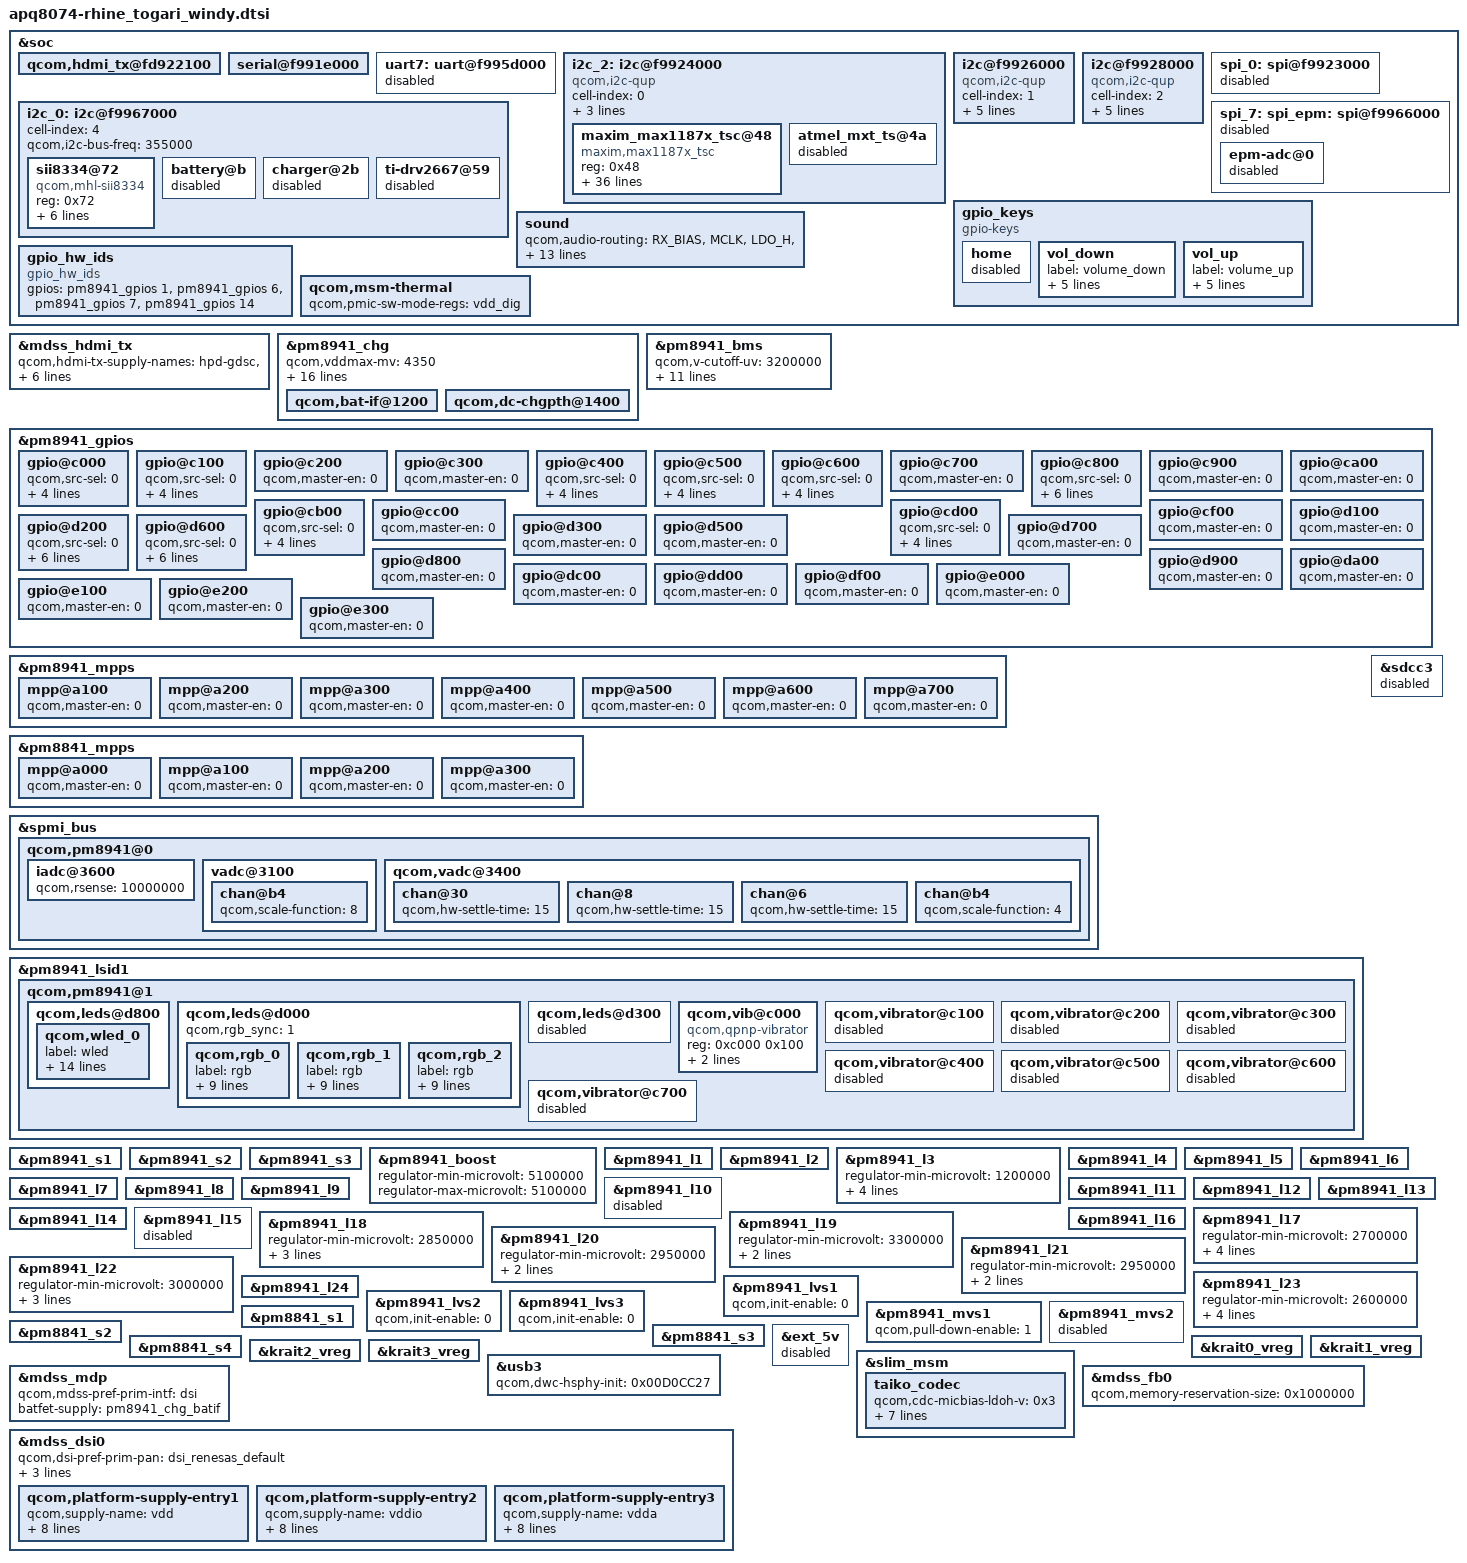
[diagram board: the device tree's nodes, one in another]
/* arch/arm/boot/dts/apq8074-rhine_togari_windy.dtsi
 *
 * Copyright (C) 2013 Sony Mobile Communications AB.
 *
 * Author: Shougo Watanabe <Shougo.X.Watanabe@sonymobile.com>
 *
 * This program is free software; you can redistribute it and/or modify
 * it under the terms of the GNU General Public License version 2 and
 * only version 2 as published by the Free Software Foundation.
 *
 * This program is distributed in the hope that it will be useful,
 * but WITHOUT ANY WARRANTY; without even the implied warranty of
 * MERCHANTABILITY or FITNESS FOR A PARTICULAR PURPOSE.  See the
 * GNU General Public License for more details.
 */

/include/ "dsi-panel-togari.dtsi"

&soc {
	qcom,hdmi_tx@fd922100 {
		status = "ok";
	};

	/* BLSP2 */
	serial@f991e000 {
		status = "ok";
	};

	/* BLSP7 */
	uart7: uart@f995d000 {
		status = "disabled";
	};

	/* BLSP2 */
	i2c_2: i2c@f9924000 {
		cell-index = <0>;
		compatible = "qcom,i2c-qup";
		qcom,i2c-bus-freq = <355000>;
		qcom,scl-gpio = <&msmgpio 7 0x00>;
		qcom,sda-gpio = <&msmgpio 6 0x00>;
		status = "ok";
		maxim_max1187x_tsc@48 {
			compatible = "maxim,max1187x_tsc";
			reg = <0x48>;
			interrupt-parent = <&msmgpio>;
			interrupts = <61 0x2>;
			touch_vdd-supply = <&pm8941_l22>;
			touch_vdd-supply_name = "touch_vdd";
			gpio_tirq = <61>;
			gpio_pwr_en = <85>;
			num_fw_mappings = <5>;
			config_id = <0x0460 0x0010 0x0011 0x0012 0x0013>;
			chip_id = <0x74 0x75 0x74 0x75 0x75>;
			filename = "touch_chip_id_0x74_config_id_0x0460.bin",
				   "touch_chip_id_0x75_config_id_0x0010.bin",
				   "touch_chip_id_0x74_config_id_0x0011.bin",
				   "touch_chip_id_0x75_config_id_0x0012.bin",
				   "touch_chip_id_0x75_config_id_0x0013.bin";
			filesize = <0xC000 0xC000 0xC000 0xC000 0xC000>;
			file_codesize = <0xC000 0xC000 0xC000 0xC000 0xC000>;
			defaults_allow = <0>;
			default_config_id = <0>;
			default_chip_id = <0>;
			i2c_words = <128>;
			coordinate_settings = <0x4>;
			panel_margin_xl = <0>;
			lcd_x = <1080>;
			panel_margin_xh = <0>;
			panel_margin_yl = <0>;
			lcd_y = <1920>;
			panel_margin_yh = <0>;
			num_sensor_x = <24>;
			num_sensor_y = <40>;
			button_code0 = <0>;
			button_code1 = <0>;
			button_code2 = <0>;
			button_code3 = <0>;
			enable_resume_por = <1>;
		};

		atmel_mxt_ts@4a {
			status = "disabled";
		};
	};

	/* BLSP4 */
	i2c@f9926000 {
		cell-index = <1>;
		compatible = "qcom,i2c-qup";
		reg = <0xf9926000 0x1000>;
		#address-cells = <1>;
		#size-cells = <0>;
		reg-names = "qup_phys_addr";
		interrupts = <0 98 0>;
		interrupt-names = "qup_err_intr";
		qcom,i2c-bus-freq = <355000>;
		qcom,i2c-src-freq = <50000000>;
		qcom,master-id = <86>;
		status = "ok";
	};

	/* BLSP6 */
	i2c@f9928000 {
		cell-index = <2>;
		compatible = "qcom,i2c-qup";
		reg = <0xf9928000 0x1000>;
		#address-cells = <1>;
		#size-cells = <0>;
		reg-names = "qup_phys_addr";
		interrupts = <0 100 0>;
		interrupt-names = "qup_err_intr";
		qcom,i2c-bus-freq = <355000>;
		qcom,i2c-src-freq = <50000000>;
		qcom,master-id = <86>;
		status = "ok";
	};

	/* BLSP11 */
	i2c_0: i2c@f9967000 {
		cell-index = <4>;
		qcom,i2c-bus-freq = <355000>;
		status = "ok";
		sii8334@72 {
			compatible = "qcom,mhl-sii8334";
			reg = <0x72>;
			interrupt-parent = <&msmgpio>;
			interrupts = <64 0x2008>;
			mhl-intr-gpio = <&msmgpio 64 0>;
			mhl-pwr-gpio = <&msmgpio 60 0>;
			mhl-rst-gpio = <&msmgpio 16 0>;
			qcom,hdmi-tx-map = <&mdss_hdmi_tx>;
		};

		battery@b {
			status = "disabled";
		};

		charger@2b {
			status = "disabled";
		};

		ti-drv2667@59 {
			status = "disabled";
		};
	};

	/* BLSP1 */
	spi_0: spi@f9923000 {
		status = "disabled";
	};

	/* BLSP10 */
	spi_7: spi_epm: spi@f9966000 {
		status = "disabled";

		epm-adc@0 {
			status = "disabled";
		};
	};

	gpio_keys {
		compatible = "gpio-keys";

		home {
			status = "disabled";
		};

		vol_down {
			label = "volume_down";
			gpios = <&pm8941_gpios 2 0x1>;
			linux,input-type = <1>;
			linux,code = <114>;
			gpio-key,wakeup;
			debounce-interval = <15>;
		};

		vol_up {
			label = "volume_up";
			gpios = <&pm8941_gpios 5 0x1>;
			linux,input-type = <1>;
			linux,code = <115>;
			gpio-key,wakeup;
			debounce-interval = <15>;
		};
	};

	sound {
		qcom,audio-routing =
			"RX_BIAS", "MCLK",
			"LDO_H", "MCLK",
			"Ext Spk Bottom Pos", "LINEOUT1",
			"Ext Spk Bottom Neg", "LINEOUT3",
			"Ext Spk Top Pos", "LINEOUT2",
			"Ext Spk Top Neg", "LINEOUT4",
			"AMIC1", "MIC BIAS1 External",
			"MIC BIAS1 External", "Handset Mic",
			"AMIC2", "MIC BIAS2 External",
			"MIC BIAS2 External", "Headset Mic",
			"AMIC3", "MIC BIAS3 External",
			"MIC BIAS3 External", "ANCLeft Headset Mic",
			"AMIC4", "MIC BIAS1 External",
			"MIC BIAS1 External", "Handset Mic",
			"AMIC5", "MIC BIAS1 External",
			"MIC BIAS1 External", "Secondary Mic",
			"AMIC6", "MIC BIAS4 External",
			"MIC BIAS4 External", "Handset FB ANC Mic";

		/delete-property/ qcom,ext-spk-amp-supply;
		/delete-property/ qcom,ext-spk-amp-gpio;
		/delete-property/ qcom,dock-plug-det-irq;
		/delete-property/ qcom,ext-ult-spk-amp-gpio;
	};

	gpio_hw_ids {
		compatible = "gpio_hw_ids";

		gpios = <&pm8941_gpios 1 0>,
			<&pm8941_gpios 6 0>,
			<&pm8941_gpios 7 0>,
			<&pm8941_gpios 14 0>;
	};

	qcom,msm-thermal {
		qcom,pmic-sw-mode-regs = "vdd_dig";
	};

	/delete-node/ ath_chip_reset;
	/delete-node/ bt_ar3002;
	/delete-node/ bt_ar3002_sleep;
	/delete-node/ qca,wlan;
	/delete-node/ qca,wlan_sdio;
};

&mdss_hdmi_tx {
	/* rhine doesn't use hpd-5v */
	qcom,hdmi-tx-supply-names = "hpd-gdsc", "core-vdda", "core-vcc";
	qcom,hdmi-tx-min-voltage-level = <0 1800000 1800000>;
	qcom,hdmi-tx-max-voltage-level = <0 1800000 1800000>;
	qcom,hdmi-tx-peak-current = <0 300000 0>;
};

&pm8941_chg {
	qcom,vddmax-mv = <4350>;
	qcom,vddsafe-mv = <4400>;
	qcom,ibatmax-ma = <2000>;
	qcom,ibatterm-ma = <150>;
	qcom,ibatsafe-ma = <2000>;
	qcom,maxinput-dc-ma = <1800>;
	qcom,maxinput-usb-ma = <1500>;
	qcom,cool-bat-mv = <4350>;
	qcom,ibatmax-warm-ma = <900>;
	qcom,warm-bat-mv = <4200>;
	qcom,ibatmax-cool-ma = <900>;
	qcom,vbatdet-delta-mv = <20>;
	qcom,vbatdet-delta-soc = <1>;
	qcom,thermal-mitigation = <2000 1500 1100 900 700 500 300 200 100 0>;
	qcom,tchg-mins = <512>;
	otg-parent-supply = <&pm8941_boost>;

	qcom,bat-if@1200 {
		status = "ok";
	};

	qcom,dc-chgpth@1400 {
		status = "ok";
	};
};

&pm8941_bms {
	status = "ok";
	qcom,v-cutoff-uv = <3200000>;
	qcom,max-voltage-uv = <4350000>;
	qcom,r-conn-mohm = <0>;
	qcom,low-soc-calculate-soc-threshold = <5>;
	qcom,low-soc-calculate-soc-ms = <1000>;
	qcom,calculate-soc-ms = <30000>;
	qcom,chg-term-ua = <150000>;
	qcom,use-external-rsense = <1>;
	qcom,batt-type = <3>;
	qcom,shutdown-soc-valid-limit = <40>;
	qcom,clamp-soc-max-count = <2>;
	qcom,fcc-resolution = <13>;
};

&pm8941_gpios {
	/* GPIO_1: HW_ID_0 */
	gpio@c000 {
		qcom,src-sel = <0>;		/* GPIO */
		qcom,mode = <0>;		/* In */
		qcom,vin-sel = <2>;		/* S3 */
		qcom,pull = <5>;		/* NP */
		qcom,master-en = <1>;		/* Enable */
		status = "ok";
	};

	/* GPIO_2: VOL_DN */
	gpio@c100 {
		qcom,src-sel = <0>;		/* GPIO */
		qcom,mode = <0>;		/* In */
		qcom,vin-sel = <2>;		/* S3 */
		qcom,pull = <0>;		/* PU */
		qcom,master-en = <1>;		/* Enable */
		status = "ok";
	};

	/* GPIO_3: NC (SNAPSHOT) */
	gpio@c200 {
		qcom,master-en = <0>;		/* Disable */
		status = "ok";
	};

	/* GPIO_4: NC (FOCUS) */
	gpio@c300 {
		qcom,master-en = <0>;		/* Disable */
		status = "ok";
	};

	/* GPIO_5: VOL_UP */
	gpio@c400 {
		qcom,src-sel = <0>;		/* GPIO */
		qcom,mode = <0>;		/* In */
		qcom,vin-sel = <2>;		/* S3 */
		qcom,pull = <0>;		/* PU */
		qcom,master-en = <1>;		/* Enable */
		status = "ok";
	};

	/* GPIO_6: HW_ID_1 */
	gpio@c500 {
		qcom,src-sel = <0>;		/* GPIO */
		qcom,mode = <0>;		/* In */
		qcom,vin-sel = <2>;		/* S3 */
		qcom,pull = <5>;		/* NP */
		qcom,master-en = <1>;		/* Enable */
		status = "ok";
	};

	/* GPIO_7: HW_ID_2 */
	gpio@c600 {
		qcom,src-sel = <0>;		/* GPIO */
		qcom,mode = <0>;		/* In */
		qcom,vin-sel = <2>;		/* S3 */
		qcom,pull = <5>;		/* NP */
		qcom,master-en = <1>;		/* Enable */
		status = "ok";
	};

	/* GPIO_8: NC */
	gpio@c700 {
		qcom,master-en = <0>;		/* Disable */
		status = "ok";
	};

	/* GPIO_9: RF_ID_EN */
	gpio@c800 {
		qcom,src-sel = <0>;		/* GPIO */
		qcom,mode = <1>;		/* Out */
		qcom,output-type = <0>;		/* CMOS */
		qcom,vin-sel = <2>;		/* S3 */
		qcom,out-strength = <3>;	/* High */
		qcom,invert = <0>;		/* Low */
		qcom,master-en = <1>;		/* Enable */
		status = "ok";
	};

	/* GPIO_10: NC (FCHG_CNT) */
	gpio@c900 {
		qcom,master-en = <0>;		/* Disable */
		status = "ok";
	};

	/* GPIO_11: NC (AUD_DSP_PWR_EN) */
	gpio@ca00 {
		qcom,master-en = <0>;		/* Disable */
		status = "ok";
	};

	/* GPIO_12: RF_ID_EXTENTION */
	gpio@cb00 {
		qcom,src-sel = <0>;		/* GPIO */
		qcom,mode = <0>;		/* In */
		qcom,vin-sel = <2>;		/* S3 */
		qcom,pull = <4>;		/* PD */
		qcom,master-en = <1>;		/* Enable */
		status = "ok";
	};

	/* GPIO_13: NC (TUNER_STATUS0) */
	gpio@cc00 {
		qcom,master-en = <0>;		/* Disable */
		status = "ok";
	};

	/* GPIO_14: HW_ID_3 */
	gpio@cd00 {
		qcom,src-sel = <0>;		/* GPIO */
		qcom,mode = <0>;		/* In */
		qcom,vin-sel = <2>;		/* S3 */
		qcom,pull = <4>;		/* PD */
		qcom,master-en = <1>;		/* Enable */
		status = "ok";
	};

	/* GPIO_15: DIVCLK1_CODEC */
	/* Follow QCT */

	/* GPIO_16: NC */
	gpio@cf00 {
		qcom,master-en = <0>;		/* Disable */
		status = "ok";
	};

	/* GPIO_17: (DIVCLK3) QPA_XO */
	/* Follow QCT */

	/* GPIO_18: NC (TUNER_STATUS1) */
	gpio@d100 {
		qcom,master-en = <0>;		/* Disable */
		status = "ok";
	};

	/* GPIO_19: DISP_RESET_N */
	gpio@d200 {
		qcom,src-sel = <0>;		/* GPIO */
		qcom,mode = <1>;		/* Out */
		qcom,output-type = <0>;		/* CMOS */
		qcom,vin-sel = <2>;		/* S3 */
		qcom,out-strength = <1>;	/* Low */
		qcom,invert = <0>;		/* Low */
		qcom,master-en = <1>;		/* Enable */
		status = "ok";
	};

	/* GPIO_20: NC (IR_LEVEL_EN) */
	gpio@d300 {
		qcom,master-en = <0>;		/* Disable */
		status = "ok";
	};

	/* GPIO_21: BOOST_BYP_EN */
	/* Follow QCT */

	/* GPIO_22: NC (HS_DET) */
	gpio@d500 {
		qcom,master-en = <0>;		/* Disable */
		status = "ok";
	};

	/* GPIO_23: NFC_VEN */
	gpio@d600 {
		qcom,src-sel = <0>;		/* GPIO */
		qcom,mode = <1>;		/* Out */
		qcom,output-type = <0>;		/* CMOS */
		qcom,vin-sel = <2>;		/* S3 */
		qcom,out-strength = <1>;	/* Low */
		qcom,invert = <1>;		/* High */
		qcom,master-en = <1>;		/* Enable */
		status = "ok";
	};

	/* GPIO_24: NC (NFC_EXT_LDO_EN) */
	gpio@d700 {
		qcom,master-en = <0>;		/* Disable */
		status = "ok";
	};

	/* GPIO_25: NC (IR_RESET) */
	gpio@d800 {
		qcom,master-en = <0>;		/* Disable */
		status = "ok";
	};

	/* GPIO_26: NC (TUNER_ANT_SW_EN) */
	gpio@d900 {
		qcom,master-en = <0>;		/* Disable */
		status = "ok";
	};

	/* GPIO_27: NC (FLASH_LED_NOW) */
	gpio@da00 {
		qcom,master-en = <0>;		/* Disable */
		status = "ok";
	};

	/* GPIO_28: TX_GTR_THRES */
	/* Follow QCT */

	/* GPIO_29: NC */
	gpio@dc00 {
		qcom,master-en = <0>;		/* Disable */
		status = "ok";
	};

	/* GPIO_30: NC */
	gpio@dd00 {
		qcom,master-en = <0>;		/* Disable */
		status = "ok";
	};

	/* GPIO_31: BATT_REM_ALERM */
	/* Follow QCT */

	/* GPIO_32: NC (TUNER_ANT_SW1) */
	gpio@df00 {
		qcom,master-en = <0>;		/* Disable */
		status = "ok";
	};

	/* GPIO_33: NC (FELICA_FF) */
	gpio@e000 {
		qcom,master-en = <0>;		/* Disable */
		status = "ok";
	};

	/* GPIO_34: NC (FELICA_LOCK) */
	gpio@e100 {
		qcom,master-en = <0>;		/* Disable */
		status = "ok";
	};

	/* GPIO_35: NC (Reserved for ANC_HS_DET) */
	gpio@e200 {
		qcom,master-en = <0>;		/* Disable */
		status = "ok";
	};

	/* GPIO_36: NC */
	gpio@e300 {
		qcom,master-en = <0>;		/* Disable */
		status = "ok";
	};
};

&pm8941_mpps {
	/* MPP_1: SDC_UIM_VBIAS */
	/* Follow QCT */

	/* MPP_2: NC */
	mpp@a100 {
		qcom,master-en = <0>;		/* Disable */
		status = "ok";
	};

	/* MPP_3: NC */
	mpp@a200 {
		qcom,master-en = <0>;		/* Disable */
		status = "ok";
	};

	/* MPP_4: NC */
	mpp@a300 {
		qcom,master-en = <0>;		/* Disable */
		status = "ok";
	};

	/* MPP_5: NC */
	mpp@a400 {
		qcom,master-en = <0>;		/* Disable */
		status = "ok";
	};

	/* MPP_6: NC (ACC_ADC) */
	mpp@a500 {
		qcom,master-en = <0>;		/* Disable */
		status = "ok";
	};

	/* MPP_7: RF_ID */
	mpp@a600 {
		qcom,master-en = <0>;		/* Disable */
		status = "ok";
	};

	/* MPP_8: NC */
	mpp@a700 {
		qcom,master-en = <0>;		/* Disable */
		status = "ok";
	};
};

&pm8841_mpps {
	/* MPP_1: NC (LMU_EN) */
	mpp@a000 {
		qcom,master-en = <0>;		/* Disable */
		status = "ok";
	};

	/* MPP_2: NC (FLASH_DR_RST_N) */
	mpp@a100 {
		qcom,master-en = <0>;		/* Disable */
		status = "ok";
	};

	/* MPP_3: NC */
	mpp@a200 {
		qcom,master-en = <0>;		/* Disable */
		status = "ok";
	};

	/* MPP_4: NC */
	mpp@a300 {
		qcom,master-en = <0>;		/* Disable */
		status = "ok";
	};
};

&spmi_bus {
	qcom,pm8941@0 {
		iadc@3600 {
			qcom,rsense = <10000000>;
		};
	};
};

&pm8941_lsid1 {
	qcom,pm8941@1 {
		qcom,leds@d800 {
			status = "okay";
			qcom,wled_0 {
				label = "wled";
				linux,name = "wled:backlight";
				linux,default-trigger = "bkl-trigger";
				qcom,cs-out-en = <1>;
				qcom,cabc-en = <1>;
				qcom,op-fdbck = <0>;
				qcom,default-state = "on";
				qcom,max-current = <20>;
				qcom,ctrl-delay-us = <0>;
				qcom,boost-curr-lim = <3>;
				qcom,cp-sel = <0>;
				qcom,switch-freq = <2>;
				qcom,ovp-val = <2>;
				qcom,num-strings = <2>;
				qcom,id = <0>;
			};
		};

		qcom,leds@d000 {
			status = "okay";
			qcom,rgb_sync = <1>;

			qcom,rgb_0 {
				label = "rgb";
				linux,name = "led:rgb_red";
				qcom,mode = "pwm";
				qcom,pwm-channel = <6>;
				qcom,pwm-us = <1000>;
				qcom,pwm-max-value = <31>;
				qcom,max-current = <12>;
				qcom,default-state = "off";
				qcom,id = <3>;
				linux,default-trigger = "none";
			};

			qcom,rgb_1 {
				label = "rgb";
				linux,name = "led:rgb_green";
				qcom,mode = "pwm";
				qcom,pwm-channel = <5>;
				qcom,pwm-us = <1000>;
				qcom,pwm-max-value = <32>;
				qcom,max-current = <12>;
				qcom,default-state = "off";
				qcom,id = <4>;
				linux,default-trigger = "none";
			};

			qcom,rgb_2 {
				label = "rgb";
				linux,name = "led:rgb_blue";
				qcom,mode = "pwm";
				qcom,pwm-channel = <4>;
				qcom,pwm-us = <1000>;
				qcom,pwm-max-value = <24>;
				qcom,max-current = <12>;
				qcom,default-state = "off";
				qcom,id = <5>;
				linux,default-trigger = "none";
			};
		};

		qcom,leds@d300 {
			status = "disabled";
		};

		qcom,vib@c000 {
			status = "okay";
			compatible = "qcom,qpnp-vibrator";
			reg = <0xc000 0x100>;
			label = "vibrator";
			qcom,qpnp-vib-vtg-level-mV = <3100>;
		};

		qcom,vibrator@c100 {
			status = "disabled";
		};

		qcom,vibrator@c200 {
			status = "disabled";
		};

		qcom,vibrator@c300 {
			status = "disabled";
		};

		qcom,vibrator@c400 {
			status = "disabled";
		};

		qcom,vibrator@c500 {
			status = "disabled";
		};

		qcom,vibrator@c600 {
			status = "disabled";
		};

		qcom,vibrator@c700 {
			status = "disabled";
		};
	};
};

&sdcc3 {
	status = "disable";
};

/* Regulator config */
&pm8941_s1 {
	status = "ok";
};

&pm8941_s2 {
	status = "ok";
};

&pm8941_s3 {
	status = "ok";
};

&pm8941_boost { /* VREG_5V */
	regulator-min-microvolt = <5100000>;
	regulator-max-microvolt = <5100000>;
	status = "ok";
};

&pm8941_l1 {
	status = "ok";
};

&pm8941_l2 {
	status = "ok";
};

&pm8941_l3 {
	regulator-min-microvolt = <1200000>;
	regulator-max-microvolt = <1200000>;
	qcom,init-enable = <0>;
	qcom,init-voltage = <1200000>;
	qcom,init-ldo-mode = <1>;
	status = "ok";
};

&pm8941_l4 {
	status = "ok";
};

&pm8941_l5 {
	status = "ok";
};

&pm8941_l6 {
	status = "ok";
};

&pm8941_l7 {
	status = "ok";
};

&pm8941_l8 {
	status = "ok";
};

&pm8941_l9 {
	status = "ok";
};

&pm8941_l10 {
	status = "disabled";
};

&pm8941_l11 {
	status = "ok";
};

&pm8941_l12 {
	status = "ok";
};

&pm8941_l13 {
	status = "ok";
};

&pm8941_l14 {
	status = "ok";
};

&pm8941_l15 {
	status = "disabled";
};

&pm8941_l16 {
	status = "ok";
};

&pm8941_l17 {
	regulator-min-microvolt = <2700000>;
	regulator-max-microvolt = <2700000>;
	qcom,init-enable = <0>;
	qcom,init-voltage = <2700000>;
	qcom,init-ldo-mode = <1>;
	status = "ok";
};

&pm8941_l18 {
	regulator-min-microvolt = <2850000>;
	regulator-max-microvolt = <2850000>;
	qcom,init-enable = <0>;
	qcom,init-voltage = <2850000>;
	status = "ok";
};

&pm8941_l19 {
	regulator-min-microvolt = <3300000>;
	regulator-max-microvolt = <3300000>;
	qcom,init-voltage = <3300000>;
	status = "ok";
};

&pm8941_l20 {
	regulator-min-microvolt = <2950000>;
	regulator-max-microvolt = <2950000>;
	qcom,init-voltage = <2950000>;
	status = "ok";
};

&pm8941_l21 {
	regulator-min-microvolt = <2950000>;
	regulator-max-microvolt = <2950000>;
	qcom,init-voltage = <2950000>;
	status = "ok";
};

&pm8941_l22 {
	regulator-min-microvolt = <3000000>;
	regulator-max-microvolt = <3000000>;
	qcom,init-enable = <0>;
	qcom,init-voltage = <3000000>;
	status = "ok";
};

&pm8941_l23 {
	regulator-min-microvolt = <2600000>;
	regulator-max-microvolt = <2600000>;
	qcom,init-enable = <0>;
	qcom,init-voltage = <2600000>;
	qcom,init-ldo-mode = <1>;
	status = "ok";
};

&pm8941_l24 {
	status = "ok";
};

&pm8941_lvs1 {
	qcom,init-enable = <0>;
	status = "ok";
};

&pm8941_lvs2 {
	qcom,init-enable = <0>;
	status = "ok";
};

&pm8941_lvs3 {
	qcom,init-enable = <0>;
	status = "ok";
};

&pm8941_mvs1 { /* VREG_OTG */
	qcom,pull-down-enable = <1>;
	status = "ok";
};

&pm8941_mvs2 { /* VREG_HDMI */
	status = "disabled";
};

&pm8841_s1 {
	status = "ok";
};

&pm8841_s2 {
	status = "ok";
};

&pm8841_s3 {
	status = "ok";
};

&pm8841_s4 {
	status = "ok";
};

&krait0_vreg { /* PM8821 VREG_S5 */
	status = "ok";
};

&krait1_vreg { /* PM8821 VREG_S6 */
	status = "ok";
};

&krait2_vreg { /* PM8821 VREG_S7 */
	status = "ok";
};

&krait3_vreg { /* PM8821 VREG_S8 */
	status = "ok";
};

&ext_5v {
	status = "disabled";
};

&slim_msm {
	taiko_codec {
		qcom,cdc-micbias-ldoh-v = <0x3>;
		qcom,cdc-micbias-cfilt1-mv = <2700>;
		qcom,cdc-micbias-cfilt2-mv = <2700>;
		qcom,cdc-micbias-cfilt3-mv = <2700>;
		qcom,cdc-micbias1-cfilt-sel = <0x1>;
		qcom,cdc-micbias2-cfilt-sel = <0x1>;
		qcom,cdc-micbias3-cfilt-sel = <0x1>;
		qcom,cdc-micbias4-cfilt-sel = <0x1>;
	};
};

&usb3 {
	qcom,dwc-hsphy-init = <0x00D0CC27>;
};

&spmi_bus {
	qcom,pm8941@0 {
		vadc@3100 {
			chan@b4 {
				qcom,scale-function = <8>;
			};
		};

		qcom,vadc@3400 {
			chan@30 {
				qcom,hw-settle-time = <15>;
			};

			chan@8 {
				qcom,hw-settle-time = <15>;
			};

			chan@6 {
				qcom,hw-settle-time = <15>;
			};

			chan@b4 {
				qcom,scale-function = <4>;
			};
		};
	};
};

&mdss_mdp {
	qcom,mdss-pref-prim-intf = "dsi";
	batfet-supply = <&pm8941_chg_batif>;
};

&mdss_fb0 {
	qcom,memory-reservation-size = <0x1000000>; /* size 16MB */
};

&mdss_dsi0 {
	qcom,dsi-pref-prim-pan = <&dsi_renesas_default>;
	vdd-supply = <&pm8941_lvs3>;
	qcom,platform-enable-gpio = <&msmgpio 46 1>;
	qcom,platform-lane-config = [];
	qcom,platform-supply-entry1 {
			qcom,supply-name = "vdd";
			qcom,supply-min-voltage = <0>;
			qcom,supply-max-voltage = <0>;
			qcom,supply-enable-load = <100000>;
			qcom,supply-disable-load = <100>;
			qcom,supply-pre-on-sleep = <0>;
			qcom,supply-post-on-sleep = <0>;
			qcom,supply-pre-off-sleep = <0>;
			qcom,supply-post-off-sleep = <0>;
	};
	qcom,platform-supply-entry2 {
			qcom,supply-name = "vddio";
			qcom,supply-min-voltage = <1800000>;
			qcom,supply-max-voltage = <1800000>;
			qcom,supply-enable-load = <100000>;
			qcom,supply-disable-load = <100>;
			qcom,supply-pre-on-sleep = <0>;
			qcom,supply-post-on-sleep = <0>;
			qcom,supply-pre-off-sleep = <0>;
			qcom,supply-post-off-sleep = <0>;
	};
	qcom,platform-supply-entry3 {
			qcom,supply-name = "vdda";
			qcom,supply-min-voltage = <1200000>;
			qcom,supply-max-voltage = <1200000>;
			qcom,supply-enable-load = <100000>;
			qcom,supply-disable-load = <100>;
			qcom,supply-pre-on-sleep = <0>;
			qcom,supply-post-on-sleep = <0>;
			qcom,supply-pre-off-sleep = <0>;
			qcom,supply-post-off-sleep = <0>;
	};
};
